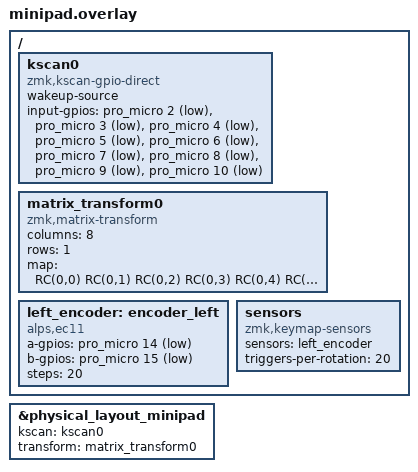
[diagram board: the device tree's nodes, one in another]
#include "minipad-layouts.dtsi"
#include <dt-bindings/zmk/matrix_transform.h>

/ {
    kscan0: kscan0 {
        compatible = "zmk,kscan-gpio-direct";
        wakeup-source;

        input-gpios
            = <&pro_micro 2 (GPIO_ACTIVE_LOW | GPIO_PULL_UP)>
            , <&pro_micro 3 (GPIO_ACTIVE_LOW | GPIO_PULL_UP)>
            , <&pro_micro 4 (GPIO_ACTIVE_LOW | GPIO_PULL_UP)>
            , <&pro_micro 5 (GPIO_ACTIVE_LOW | GPIO_PULL_UP)>
            , <&pro_micro 6 (GPIO_ACTIVE_LOW | GPIO_PULL_UP)>
            , <&pro_micro 7 (GPIO_ACTIVE_LOW | GPIO_PULL_UP)>
            , <&pro_micro 8 (GPIO_ACTIVE_LOW | GPIO_PULL_UP)>
            , <&pro_micro 9 (GPIO_ACTIVE_LOW | GPIO_PULL_UP)>
            , <&pro_micro 10 (GPIO_ACTIVE_LOW | GPIO_PULL_UP)>
            ;
    };

        matrix_transform0: matrix_transform0 {
            compatible = "zmk,matrix-transform";
            columns = <8>;
            rows = <1>;
            map = <
                RC(0,0) RC(0,1) RC(0,2) RC(0,3) RC(0,4) RC(0,5) RC(0,6) RC(0,7) RC(0,8)
                >;
    };

   
    left_encoder: encoder_left {
        compatible = "alps,ec11";
        a-gpios = <&pro_micro 14 (GPIO_ACTIVE_LOW | GPIO_PULL_UP)>;
        b-gpios = <&pro_micro 15 (GPIO_ACTIVE_LOW | GPIO_PULL_UP)>;
        steps = <20>;
        status = "okay";
    };

    sensors: sensors {
        compatible = "zmk,keymap-sensors";
        sensors = <&left_encoder>;
        triggers-per-rotation = <20>;
    };
};

&physical_layout_minipad {
    kscan = <&kscan0>;
    transform = <&matrix_transform0>;
};
